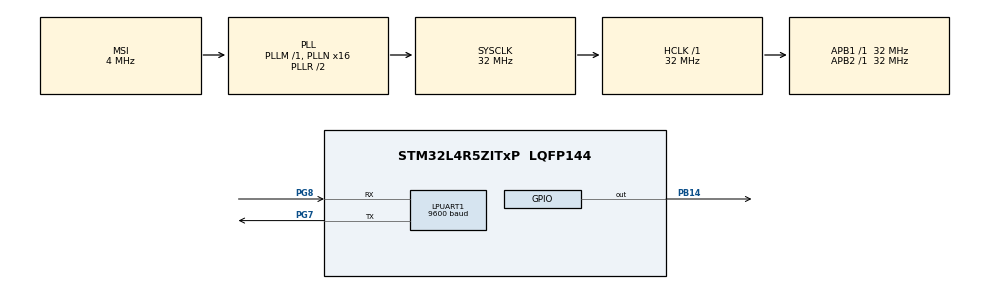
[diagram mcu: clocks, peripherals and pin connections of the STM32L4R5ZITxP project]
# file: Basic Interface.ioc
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LPUART1.BaudRate=9600
LPUART1.WordLength=UART_WORDLENGTH_8B
Mcu.Family=STM32L4
Mcu.Name=STM32L4R5ZITxP
Mcu.Package=LQFP144
NVIC.PriorityGroup=NVIC_PRIORITYGROUP_4
PB14.Signal=GPIO_Output
PG7.Mode=Asynchronous
PG7.Signal=LPUART1_TX
PG8.Mode=Asynchronous
PG8.Signal=LPUART1_RX
ProjectManager.HeapSize=0x200
ProjectManager.StackSize=0x400
ProjectManager.TargetToolchain=STM32CubeIDE
RCC.ADCFreq_Value=48000000
RCC.AHBFreq_Value=32000000
RCC.APB1Freq_Value=32000000
RCC.APB1TimFreq_Value=32000000
RCC.APB2Freq_Value=32000000
RCC.APB2TimFreq_Value=32000000
RCC.CortexFreq_Value=32000000
RCC.HCLKFreq_Value=32000000
RCC.HSE_VALUE=8000000
RCC.HSI48_VALUE=48000000
RCC.HSI_VALUE=16000000
RCC.MSI_VALUE=4000000
RCC.PLLN=16
RCC.PLLSAI1N=24
RCC.SYSCLKFreq_VALUE=32000000
RCC.SYSCLKSource=RCC_SYSCLKSOURCE_PLLCLK
RCC.USBFreq_Value=48000000
RCC.VCOOutputFreq_Value=64000000
board=NUCLEO-L4R5ZI-P

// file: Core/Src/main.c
/* USER CODE BEGIN Header */
/**
  ******************************************************************************
  * @file           : main.c
  * @brief          : Main program body
  ******************************************************************************
  * @attention
  *
  * Copyright (c) 2022 STMicroelectronics.
  * All rights reserved.
  *
  * This software is licensed under terms that can be found in the LICENSE file
  * in the root directory of this software component.
  * If no LICENSE file comes with this software, it is provided AS-IS.
  *
  ******************************************************************************
  */
/* USER CODE END Header */
#include "main.h"

/* USER CODE BEGIN Includes */
#include <stdio.h>
#include "string.h"
#include <stdint.h>
#include <stdarg.h>
/* USER CODE END Includes */

 UART_HandleTypeDef hlpuart1;

void SystemClock_Config(void);
static void MX_GPIO_Init(void);
static void MX_LPUART1_UART_Init(void);
/* USER CODE BEGIN PFP */
void printmsg(char *format,...);
/* USER CODE END PFP */

int main(void)
{

  /* MCU Configuration--------------------------------------------------------*/

  /* Reset of all peripherals, Initializes the Flash interface and the Systick. */
  HAL_Init();

  /* Configure the system clock */
  SystemClock_Config();

  /* Initialize all configured peripherals */
  MX_GPIO_Init();
  MX_LPUART1_UART_Init();
  /* USER CODE BEGIN 2 */
//printmsg("Hello world!");
uint8_t buffer[]  = "Hello world!";
if (HAL_UART_Transmit(&hlpuart1, (uint8_t *)buffer, strlen(buffer),HAL_MAX_DELAY) != HAL_OK)
{
	HAL_GPIO_WritePin(GPIOB, GPIO_PIN_7, GPIO_PIN_SET);
}

HAL_Delay(1000);
HAL_GPIO_TogglePin(GPIOB, GPIO_PIN_14);
HAL_Delay(1000);
HAL_GPIO_TogglePin(GPIOB, GPIO_PIN_14);
HAL_Delay(1000);
HAL_GPIO_TogglePin(GPIOB, GPIO_PIN_14);

  /* USER CODE END 2 */

  /* Infinite loop */
  while (1)
  {

  }
}

void SystemClock_Config(void)
{
  RCC_OscInitTypeDef RCC_OscInitStruct = {0};
  RCC_ClkInitTypeDef RCC_ClkInitStruct = {0};

  /** Configure the main internal regulator output voltage
  */
  if (HAL_PWREx_ControlVoltageScaling(PWR_REGULATOR_VOLTAGE_SCALE1) != HAL_OK)
  {
    Error_Handler();
  }

  /** Initializes the RCC Oscillators according to the specified parameters
  * in the RCC_OscInitTypeDef structure.
  */
  RCC_OscInitStruct.OscillatorType = RCC_OSCILLATORTYPE_MSI;
  RCC_OscInitStruct.MSIState = RCC_MSI_ON;
  RCC_OscInitStruct.MSICalibrationValue = 0;
  RCC_OscInitStruct.MSIClockRange = RCC_MSIRANGE_6;
  RCC_OscInitStruct.PLL.PLLState = RCC_PLL_ON;
  RCC_OscInitStruct.PLL.PLLSource = RCC_PLLSOURCE_MSI;
  RCC_OscInitStruct.PLL.PLLM = 1;
  RCC_OscInitStruct.PLL.PLLN = 16;
  RCC_OscInitStruct.PLL.PLLP = RCC_PLLP_DIV2;
  RCC_OscInitStruct.PLL.PLLQ = RCC_PLLQ_DIV2;
  RCC_OscInitStruct.PLL.PLLR = RCC_PLLR_DIV2;
  if (HAL_RCC_OscConfig(&RCC_OscInitStruct) != HAL_OK)
  {
    Error_Handler();
  }

  /** Initializes the CPU, AHB and APB buses clocks
  */
  RCC_ClkInitStruct.ClockType = RCC_CLOCKTYPE_HCLK|RCC_CLOCKTYPE_SYSCLK
                              |RCC_CLOCKTYPE_PCLK1|RCC_CLOCKTYPE_PCLK2;
  RCC_ClkInitStruct.SYSCLKSource = RCC_SYSCLKSOURCE_PLLCLK;
  RCC_ClkInitStruct.AHBCLKDivider = RCC_SYSCLK_DIV1;
  RCC_ClkInitStruct.APB1CLKDivider = RCC_HCLK_DIV1;
  RCC_ClkInitStruct.APB2CLKDivider = RCC_HCLK_DIV1;

  if (HAL_RCC_ClockConfig(&RCC_ClkInitStruct, FLASH_LATENCY_1) != HAL_OK)
  {
    Error_Handler();
  }
}

static void MX_LPUART1_UART_Init(void)
{

  hlpuart1.Instance = LPUART1;
  hlpuart1.Init.BaudRate = 9600;
  hlpuart1.Init.WordLength = UART_WORDLENGTH_8B;
  hlpuart1.Init.StopBits = UART_STOPBITS_1;
  hlpuart1.Init.Parity = UART_PARITY_NONE;
  hlpuart1.Init.Mode = UART_MODE_TX_RX;
  hlpuart1.Init.HwFlowCtl = UART_HWCONTROL_NONE;
  hlpuart1.Init.OneBitSampling = UART_ONE_BIT_SAMPLE_DISABLE;
  hlpuart1.Init.ClockPrescaler = UART_PRESCALER_DIV1;
  hlpuart1.AdvancedInit.AdvFeatureInit = UART_ADVFEATURE_NO_INIT;
  hlpuart1.FifoMode = UART_FIFOMODE_DISABLE;
  if (HAL_UART_Init(&hlpuart1) != HAL_OK)
  {
    Error_Handler();
  }
  if (HAL_UARTEx_SetTxFifoThreshold(&hlpuart1, UART_TXFIFO_THRESHOLD_1_8) != HAL_OK)
  {
    Error_Handler();
  }
  if (HAL_UARTEx_SetRxFifoThreshold(&hlpuart1, UART_RXFIFO_THRESHOLD_1_8) != HAL_OK)
  {
    Error_Handler();
  }
  if (HAL_UARTEx_DisableFifoMode(&hlpuart1) != HAL_OK)
  {
    Error_Handler();
  }

}

static void MX_GPIO_Init(void)
{
  GPIO_InitTypeDef GPIO_InitStruct = {0};

  /* GPIO Ports Clock Enable */
  __HAL_RCC_GPIOB_CLK_ENABLE();
  __HAL_RCC_GPIOG_CLK_ENABLE();
  HAL_PWREx_EnableVddIO2();

  /*Configure GPIO pin Output Level */
  HAL_GPIO_WritePin(GPIOB, GPIO_PIN_14, GPIO_PIN_RESET);

  /*Configure GPIO pin : PB14 */
  GPIO_InitStruct.Pin = GPIO_PIN_14;
  GPIO_InitStruct.Mode = GPIO_MODE_OUTPUT_PP;
  GPIO_InitStruct.Pull = GPIO_NOPULL;
  GPIO_InitStruct.Speed = GPIO_SPEED_FREQ_LOW;
  HAL_GPIO_Init(GPIOB, &GPIO_InitStruct);

}

/* USER CODE BEGIN 4 */
void printmsg(char *format,...) {
    char str[30];

    /*Extract the the argument list using VA apis */
    va_list args;
    va_start(args, format);
    vsprintf(str, format,args);
    //HAL_UART_Transmit(&hlpuart1,(uint8_t *)str, strlen(str),HAL_MAX_DELAY);
    va_end(args);
}
/* USER CODE END 4 */

void Error_Handler(void)
{
  __disable_irq();
  while (1)
  {
  }
}
